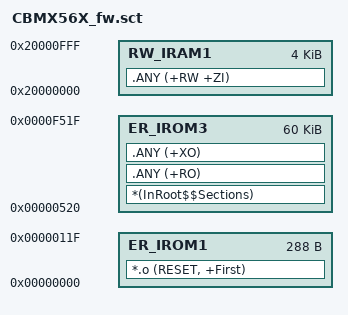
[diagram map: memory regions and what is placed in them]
; *************************************************************
; *** Scatter-Loading Description File generated by uVision ***
; *************************************************************

LR_IROM1 0x00000000 0x00000120  {    ; load region size_region
  ER_IROM1 0x00000000 0x00000120  {  ; load address = execution address
   *.o (RESET, +First)
  }
}

LR_IROM2 0x00000120 0x00000400  {    ; load region size_region  1k for RW data
  RW_IRAM1 0x20000000 0x00001000  {  ; RW data
   .ANY (+RW +ZI)
  }
}

LR_IROM3 0x00000520 0x0000F000  {    ; load region size_region
  ER_IROM3 0x00000520 0x0000F000  {  ; load address = execution address
   *(InRoot$$Sections)
   .ANY (+RO)
   .ANY (+XO)
  }
}
